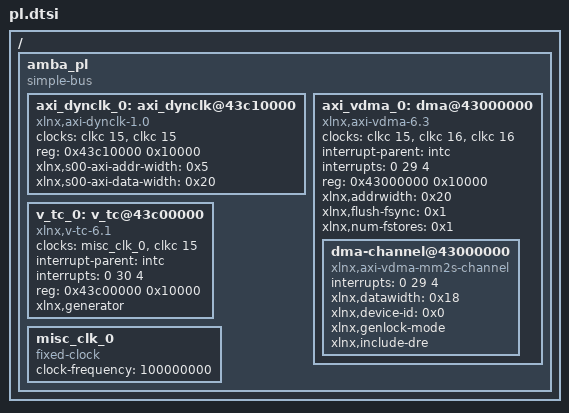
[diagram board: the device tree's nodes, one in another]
/*
 * CAUTION: This file is automatically generated by Xilinx.
 * Version:  
 * Today is: Sat Nov 28 07:43:17 2020
 */


/ {
	amba_pl: amba_pl {
		#address-cells = <1>;
		#size-cells = <1>;
		compatible = "simple-bus";
		ranges ;
		axi_dynclk_0: axi_dynclk@43c10000 {
			clock-names = "REF_CLK_I", "s00_axi_aclk";
			clocks = <&clkc 15>, <&clkc 15>;
			compatible = "xlnx,axi-dynclk-1.0";
			reg = <0x43c10000 0x10000>;
			xlnx,s00-axi-addr-width = <0x5>;
			xlnx,s00-axi-data-width = <0x20>;
		};
		axi_vdma_0: dma@43000000 {
			#dma-cells = <1>;
			clock-names = "s_axi_lite_aclk", "m_axi_mm2s_aclk", "m_axis_mm2s_aclk";
			clocks = <&clkc 15>, <&clkc 16>, <&clkc 16>;
			compatible = "xlnx,axi-vdma-6.3", "xlnx,axi-vdma-1.00.a";
			interrupt-names = "mm2s_introut";
			interrupt-parent = <&intc>;
			interrupts = <0 29 4>;
			reg = <0x43000000 0x10000>;
			xlnx,addrwidth = <0x20>;
			xlnx,flush-fsync = <0x1>;
			xlnx,num-fstores = <0x1>;
			dma-channel@43000000 {
				compatible = "xlnx,axi-vdma-mm2s-channel";
				interrupts = <0 29 4>;
				xlnx,datawidth = <0x18>;
				xlnx,device-id = <0x0>;
				xlnx,genlock-mode ;
				xlnx,include-dre ;
			};
		};
		v_tc_0: v_tc@43c00000 {
			clock-names = "clk", "s_axi_aclk";
			clocks = <&misc_clk_0>, <&clkc 15>;
			compatible = "xlnx,v-tc-6.1", "xlnx,v-tc-6.1";
			interrupt-names = "irq";
			interrupt-parent = <&intc>;
			interrupts = <0 30 4>;
			reg = <0x43c00000 0x10000>;
			xlnx,generator ;
		};
		misc_clk_0: misc_clk_0 {
			#clock-cells = <0>;
			clock-frequency = <100000000>;
			compatible = "fixed-clock";
		};
	};
};
